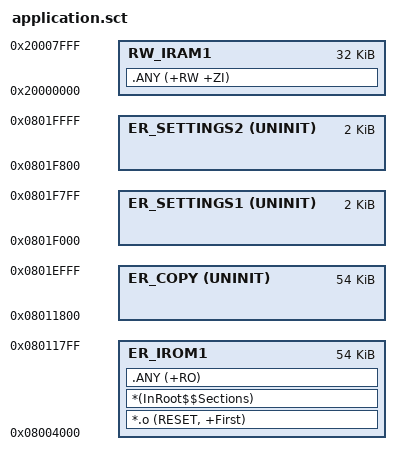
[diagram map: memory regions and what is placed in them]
; STM32F303CBT6 application image
; MAIN occupies exactly 54 KiB: 0x08004000..0x080117FF.
; BACKUP occupies exactly 54 KiB: 0x08011800..0x0801EFFF.
; Settings are two independent 2 KiB erase pages at 0x0801F000/0x0801F800.

LR_IROM1 0x08004000 0x0000D800
{
    ER_IROM1 0x08004000 0x0000D800
    {
        *.o (RESET, +First)
        *(InRoot$$Sections)
        .ANY (+RO)
    }

    RW_IRAM1 0x20000000 0x00008000
    {
        .ANY (+RW +ZI)
    }
}

LR_COPY 0x08011800 0x0000D800
{
    ER_COPY 0x08011800 0x0000D800 UNINIT
    {
    }
}

LR_SETTINGS1 0x0801F000 0x00000800
{
    ER_SETTINGS1 0x0801F000 0x00000800 UNINIT
    {
    }
}

LR_SETTINGS2 0x0801F800 0x00000800
{
    ER_SETTINGS2 0x0801F800 0x00000800 UNINIT
    {
    }
}
